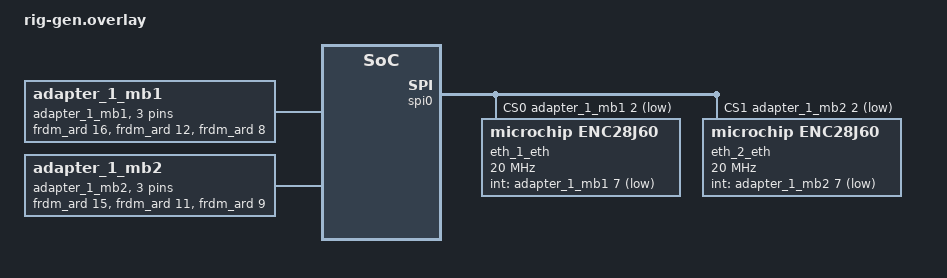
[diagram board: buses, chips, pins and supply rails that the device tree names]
/* generated by rigexp — do not edit; the rig file is the source of truth (R3)
 * rig: frdm_eth_nest  board: frdm_k64f/mk64f12/rig
 */

/* carrier-exported sockets, synthesized as gpio-nexus nodes */
/ {
	adapter_1_mb1: adapter_1_mb1 {
		#gpio-cells = <2>;
		gpio-map-mask = <0xffffffff 0xffffffc0>;
		gpio-map-pass-thru = <0 0x3f>;
		gpio-map = <2 0 &frdm_ard 16 0>,
			   <1 0 &frdm_ard 12 0>,
			   <7 0 &frdm_ard 8 0>;
	};
	adapter_1_mb2: adapter_1_mb2 {
		#gpio-cells = <2>;
		gpio-map-mask = <0xffffffff 0xffffffc0>;
		gpio-map-pass-thru = <0 0x3f>;
		gpio-map = <2 0 &frdm_ard 15 0>,
			   <1 0 &frdm_ard 11 0>,
			   <7 0 &frdm_ard 9 0>;
	};
};

&spi0 {
	cs-gpios = <&adapter_1_mb1 2 1 /* ACTIVE_LOW */>, <&adapter_1_mb2 2 1 /* ACTIVE_LOW */>;
	eth_1_eth: eth@0 {
		compatible = "microchip,enc28j60";
		spi-max-frequency = <20000000>;
		local-mac-address = [00 00 00 00 00 00];
		zephyr,random-mac-address;
		reg = <0>;
		int-gpios = <&adapter_1_mb1 7 0x1>;	/* INT */
		status = "okay";
	};
	eth_2_eth: eth@1 {
		compatible = "microchip,enc28j60";
		spi-max-frequency = <20000000>;
		local-mac-address = [00 00 00 00 00 00];
		zephyr,random-mac-address;
		reg = <1>;
		int-gpios = <&adapter_1_mb2 7 0x1>;	/* INT */
		status = "okay";
	};
};
